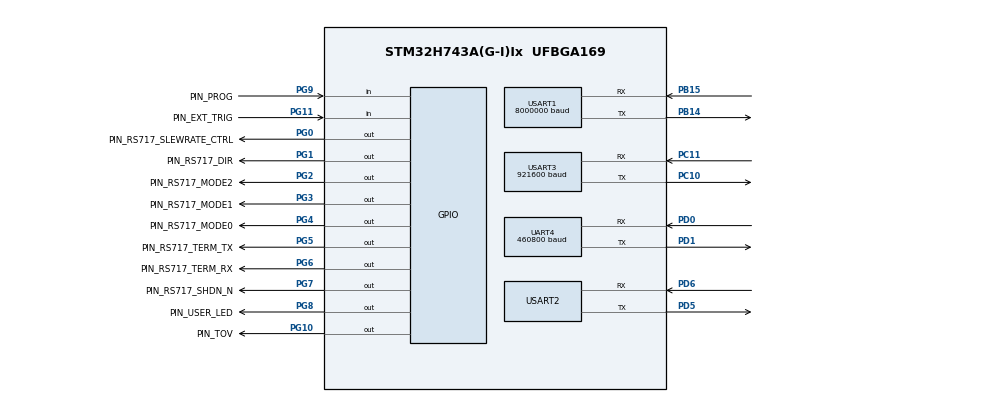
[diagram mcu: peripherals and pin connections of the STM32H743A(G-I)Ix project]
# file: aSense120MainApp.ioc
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CORTEX_M7.AccessPermission-Cortex_Memory_Protection_Unit_Region0_Settings=MPU_REGION_FULL_ACCESS
CORTEX_M7.AccessPermission_Spec=MPU_REGION_FULL_ACCESS
CORTEX_M7.BaseAddress-Cortex_Memory_Protection_Unit_Region0_Settings=0x2407F000
CORTEX_M7.BaseAddress_Spec=0x2407C000
CORTEX_M7.CPU_DCache=Enabled
CORTEX_M7.CPU_ICache=Enabled
CORTEX_M7.DisableExec_Spec=MPU_INSTRUCTION_ACCESS_ENABLE
CORTEX_M7.Enable-Cortex_Memory_Protection_Unit_Region0_Settings=MPU_REGION_ENABLE
CORTEX_M7.IsBufferable-Cortex_Memory_Protection_Unit_Region0_Settings=MPU_ACCESS_BUFFERABLE
CORTEX_M7.IsBufferable_Spec=MPU_ACCESS_BUFFERABLE
CORTEX_M7.IsShareable-Cortex_Memory_Protection_Unit_Region0_Settings=MPU_ACCESS_SHAREABLE
CORTEX_M7.MPU_Control=MPU_PRIVILEGED_DEFAULT
CORTEX_M7.Size-Cortex_Memory_Protection_Unit_Region0_Settings=MPU_REGION_SIZE_4KB
CORTEX_M7.Size_Spec=MPU_REGION_SIZE_16KB
CORTEX_M7.SubRegionDisable_Spec=0x0
CORTEX_M7.TypeExtField_Spec=MPU_TEX_LEVEL0
CORTEX_M7.default_mode_Activation=1
Dma.Request0=USART1_RX
Dma.Request1=USART1_TX
Dma.Request2=UART4_RX
Dma.Request3=UART4_TX
Dma.Request4=USART3_RX
Dma.Request5=USART3_TX
Dma.Request6=USART2_RX
Dma.Request7=USART2_TX
Dma.UART4_RX.2.Direction=DMA_PERIPH_TO_MEMORY
Dma.UART4_RX.2.EventEnable=DISABLE
Dma.UART4_RX.2.FIFOMode=DMA_FIFOMODE_DISABLE
Dma.UART4_RX.2.Instance=DMA1_Stream4
Dma.UART4_RX.2.MemDataAlignment=DMA_MDATAALIGN_BYTE
Dma.UART4_RX.2.MemInc=DMA_MINC_ENABLE
Dma.UART4_RX.2.Mode=DMA_NORMAL
Dma.UART4_RX.2.PeriphDataAlignment=DMA_PDATAALIGN_BYTE
Dma.UART4_RX.2.PeriphInc=DMA_PINC_DISABLE
Dma.UART4_RX.2.Polarity=HAL_DMAMUX_REQ_GEN_RISING
Dma.UART4_RX.2.Priority=DMA_PRIORITY_LOW
Dma.UART4_RX.2.RequestNumber=1
Dma.UART4_RX.2.SignalID=NONE
Dma.UART4_RX.2.SyncEnable=DISABLE
Dma.UART4_RX.2.SyncPolarity=HAL_DMAMUX_SYNC_NO_EVENT
Dma.UART4_RX.2.SyncRequestNumber=1
Dma.UART4_RX.2.SyncSignalID=NONE
Dma.UART4_TX.3.Direction=DMA_MEMORY_TO_PERIPH
Dma.UART4_TX.3.EventEnable=DISABLE
Dma.UART4_TX.3.FIFOMode=DMA_FIFOMODE_DISABLE
Dma.UART4_TX.3.Instance=DMA1_Stream5
Dma.UART4_TX.3.MemDataAlignment=DMA_MDATAALIGN_BYTE
Dma.UART4_TX.3.MemInc=DMA_MINC_ENABLE
Dma.UART4_TX.3.Mode=DMA_NORMAL
Dma.UART4_TX.3.PeriphDataAlignment=DMA_PDATAALIGN_BYTE
Dma.UART4_TX.3.PeriphInc=DMA_PINC_DISABLE
Dma.UART4_TX.3.Polarity=HAL_DMAMUX_REQ_GEN_RISING
Dma.UART4_TX.3.Priority=DMA_PRIORITY_LOW
Dma.UART4_TX.3.RequestNumber=1
Dma.UART4_TX.3.SignalID=NONE
Dma.UART4_TX.3.SyncEnable=DISABLE
Dma.UART4_TX.3.SyncPolarity=HAL_DMAMUX_SYNC_NO_EVENT
Dma.UART4_TX.3.SyncRequestNumber=1
Dma.UART4_TX.3.SyncSignalID=NONE
Dma.USART1_RX.0.Direction=DMA_PERIPH_TO_MEMORY
Dma.USART1_RX.0.EventEnable=DISABLE
Dma.USART1_RX.0.FIFOMode=DMA_FIFOMODE_DISABLE
Dma.USART1_RX.0.Instance=DMA1_Stream0
Dma.USART1_RX.0.MemDataAlignment=DMA_MDATAALIGN_BYTE
Dma.USART1_RX.0.MemInc=DMA_MINC_ENABLE
Dma.USART1_RX.0.Mode=DMA_NORMAL
Dma.USART1_RX.0.PeriphDataAlignment=DMA_PDATAALIGN_BYTE
Dma.USART1_RX.0.PeriphInc=DMA_PINC_DISABLE
Dma.USART1_RX.0.Polarity=HAL_DMAMUX_REQ_GEN_RISING
Dma.USART1_RX.0.Priority=DMA_PRIORITY_LOW
Dma.USART1_RX.0.RequestNumber=1
Dma.USART1_RX.0.SignalID=NONE
Dma.USART1_RX.0.SyncEnable=DISABLE
Dma.USART1_RX.0.SyncPolarity=HAL_DMAMUX_SYNC_NO_EVENT
Dma.USART1_RX.0.SyncRequestNumber=1
Dma.USART1_RX.0.SyncSignalID=NONE
Dma.USART1_TX.1.Direction=DMA_MEMORY_TO_PERIPH
Dma.USART1_TX.1.EventEnable=DISABLE
Dma.USART1_TX.1.FIFOMode=DMA_FIFOMODE_DISABLE
Dma.USART1_TX.1.Instance=DMA1_Stream1
Dma.USART1_TX.1.MemDataAlignment=DMA_MDATAALIGN_BYTE
Dma.USART1_TX.1.MemInc=DMA_MINC_ENABLE
Dma.USART1_TX.1.Mode=DMA_NORMAL
Dma.USART1_TX.1.PeriphDataAlignment=DMA_PDATAALIGN_BYTE
Dma.USART1_TX.1.PeriphInc=DMA_PINC_DISABLE
Dma.USART1_TX.1.Polarity=HAL_DMAMUX_REQ_GEN_RISING
Dma.USART1_TX.1.Priority=DMA_PRIORITY_LOW
Dma.USART1_TX.1.RequestNumber=1
Dma.USART1_TX.1.SignalID=NONE
Dma.USART1_TX.1.SyncEnable=DISABLE
Dma.USART1_TX.1.SyncPolarity=HAL_DMAMUX_SYNC_NO_EVENT
Dma.USART1_TX.1.SyncRequestNumber=1
Dma.USART1_TX.1.SyncSignalID=NONE
Dma.USART2_RX.6.Direction=DMA_PERIPH_TO_MEMORY
Dma.USART2_RX.6.EventEnable=DISABLE
Dma.USART2_RX.6.FIFOMode=DMA_FIFOMODE_DISABLE
Dma.USART2_RX.6.Instance=DMA1_Stream2
Dma.USART2_RX.6.MemDataAlignment=DMA_MDATAALIGN_BYTE
Dma.USART2_RX.6.MemInc=DMA_MINC_ENABLE
Dma.USART2_RX.6.Mode=DMA_NORMAL
Dma.USART2_RX.6.PeriphDataAlignment=DMA_PDATAALIGN_BYTE
Dma.USART2_RX.6.PeriphInc=DMA_PINC_DISABLE
Dma.USART2_RX.6.Polarity=HAL_DMAMUX_REQ_GEN_RISING
Dma.USART2_RX.6.Priority=DMA_PRIORITY_LOW
Dma.USART2_RX.6.RequestNumber=1
Dma.USART2_RX.6.SignalID=NONE
Dma.USART2_RX.6.SyncEnable=DISABLE
Dma.USART2_RX.6.SyncPolarity=HAL_DMAMUX_SYNC_NO_EVENT
Dma.USART2_RX.6.SyncRequestNumber=1
Dma.USART2_RX.6.SyncSignalID=NONE
Dma.USART2_TX.7.Direction=DMA_MEMORY_TO_PERIPH
Dma.USART2_TX.7.EventEnable=DISABLE
Dma.USART2_TX.7.FIFOMode=DMA_FIFOMODE_DISABLE
Dma.USART2_TX.7.Instance=DMA1_Stream3
Dma.USART2_TX.7.MemDataAlignment=DMA_MDATAALIGN_BYTE
Dma.USART2_TX.7.MemInc=DMA_MINC_ENABLE
Dma.USART2_TX.7.Mode=DMA_NORMAL
Dma.USART2_TX.7.PeriphDataAlignment=DMA_PDATAALIGN_BYTE
Dma.USART2_TX.7.PeriphInc=DMA_PINC_DISABLE
Dma.USART2_TX.7.Polarity=HAL_DMAMUX_REQ_GEN_RISING
Dma.USART2_TX.7.Priority=DMA_PRIORITY_LOW
Dma.USART2_TX.7.RequestNumber=1
Dma.USART2_TX.7.SignalID=NONE
Dma.USART2_TX.7.SyncEnable=DISABLE
Dma.USART2_TX.7.SyncPolarity=HAL_DMAMUX_SYNC_NO_EVENT
Dma.USART2_TX.7.SyncRequestNumber=1
Dma.USART2_TX.7.SyncSignalID=NONE
Dma.USART3_RX.4.Direction=DMA_PERIPH_TO_MEMORY
Dma.USART3_RX.4.EventEnable=DISABLE
Dma.USART3_RX.4.FIFOMode=DMA_FIFOMODE_DISABLE
Dma.USART3_RX.4.Instance=DMA2_Stream3
Dma.USART3_RX.4.MemDataAlignment=DMA_MDATAALIGN_BYTE
Dma.USART3_RX.4.MemInc=DMA_MINC_ENABLE
Dma.USART3_RX.4.Mode=DMA_NORMAL
Dma.USART3_RX.4.PeriphDataAlignment=DMA_PDATAALIGN_BYTE
Dma.USART3_RX.4.PeriphInc=DMA_PINC_DISABLE
Dma.USART3_RX.4.Polarity=HAL_DMAMUX_REQ_GEN_RISING
Dma.USART3_RX.4.Priority=DMA_PRIORITY_LOW
Dma.USART3_RX.4.RequestNumber=1
Dma.USART3_RX.4.SignalID=NONE
Dma.USART3_RX.4.SyncEnable=DISABLE
Dma.USART3_RX.4.SyncPolarity=HAL_DMAMUX_SYNC_NO_EVENT
Dma.USART3_RX.4.SyncRequestNumber=1
Dma.USART3_RX.4.SyncSignalID=NONE
Dma.USART3_TX.5.Direction=DMA_MEMORY_TO_PERIPH
Dma.USART3_TX.5.EventEnable=DISABLE
Dma.USART3_TX.5.FIFOMode=DMA_FIFOMODE_DISABLE
Dma.USART3_TX.5.Instance=DMA2_Stream2
Dma.USART3_TX.5.MemDataAlignment=DMA_MDATAALIGN_BYTE
Dma.USART3_TX.5.MemInc=DMA_MINC_ENABLE
Dma.USART3_TX.5.Mode=DMA_NORMAL
Dma.USART3_TX.5.PeriphDataAlignment=DMA_PDATAALIGN_BYTE
Dma.USART3_TX.5.PeriphInc=DMA_PINC_DISABLE
Dma.USART3_TX.5.Polarity=HAL_DMAMUX_REQ_GEN_RISING
Dma.USART3_TX.5.Priority=DMA_PRIORITY_LOW
Dma.USART3_TX.5.RequestNumber=1
Dma.USART3_TX.5.SignalID=NONE
Dma.USART3_TX.5.SyncEnable=DISABLE
Dma.USART3_TX.5.SyncPolarity=HAL_DMAMUX_SYNC_NO_EVENT
Dma.USART3_TX.5.SyncRequestNumber=1
Dma.USART3_TX.5.SyncSignalID=NONE
Mcu.Family=STM32H7
Mcu.Name=STM32H743A(G-I)Ix
Mcu.Package=UFBGA169
Mcu.UserConstants=UART_RS717,$$_USART3_IP_HANDLE_$$;UART_EXT_IF,$$_USART1_IP_HANDLE_$$;UART_DELTAIMU,$$_UART4_IP_HANDLE_$$
NVIC.DMA1_Stream0_IRQn=true\:0\:0\:true\:false\:true\:true\:false\:true\:true
NVIC.DMA1_Stream1_IRQn=true\:0\:0\:true\:false\:true\:true\:false\:true\:true
NVIC.DMA1_Stream2_IRQn=true\:0\:0\:false\:false\:true\:true\:false\:true\:true
NVIC.DMA1_Stream3_IRQn=true\:0\:0\:false\:false\:true\:true\:false\:true\:true
NVIC.DMA1_Stream4_IRQn=true\:0\:0\:true\:false\:true\:true\:false\:true\:true
NVIC.DMA1_Stream5_IRQn=true\:0\:0\:true\:false\:true\:true\:false\:true\:true
NVIC.DMA2_Stream2_IRQn=true\:0\:0\:false\:false\:true\:false\:false\:true\:true
NVIC.DMA2_Stream3_IRQn=true\:0\:0\:false\:false\:true\:false\:false\:true\:true
NVIC.PriorityGroup=NVIC_PRIORITYGROUP_4
NVIC.TIM3_IRQn=true\:0\:0\:false\:false\:true\:false\:true\:true\:true
NVIC.TIM6_DAC_IRQn=true\:15\:0\:true\:false\:true\:false\:false\:true\:true
NVIC.TimeBase=TIM6_DAC_IRQn
NVIC.TimeBaseIP=TIM6
NVIC.UART4_IRQn=true\:0\:0\:true\:false\:true\:false\:true\:true\:true
NVIC.USART1_IRQn=true\:0\:0\:true\:false\:true\:false\:true\:true\:true
NVIC.USART2_IRQn=true\:0\:0\:false\:false\:true\:false\:true\:true\:true
NVIC.USART3_IRQn=true\:0\:0\:true\:false\:true\:false\:true\:true\:true
PA13\ (JTMS/SWDIO).Mode=Serial_Wire
PA13\ (JTMS/SWDIO).Signal=DEBUG_JTMS-SWDIO
PA14\ (JTCK/SWCLK).Mode=Serial_Wire
PA14\ (JTCK/SWCLK).Signal=DEBUG_JTCK-SWCLK
PB14.GPIO_PuPd=GPIO_PULLUP
PB14.GPIO_Speed=GPIO_SPEED_FREQ_VERY_HIGH
PB14.Mode=Asynchronous
PB14.Signal=USART1_TX
PB15.GPIO_PuPd=GPIO_PULLUP
PB15.GPIO_Speed=GPIO_SPEED_FREQ_VERY_HIGH
PB15.Mode=Asynchronous
PB15.Signal=USART1_RX
PC10.GPIO_PuPd=GPIO_PULLUP
PC10.GPIO_Speed=GPIO_SPEED_FREQ_VERY_HIGH
PC10.Mode=Asynchronous
PC10.Signal=USART3_TX
PC11.GPIO_PuPd=GPIO_PULLUP
PC11.GPIO_Speed=GPIO_SPEED_FREQ_VERY_HIGH
PC11.Mode=Asynchronous
PC11.Signal=USART3_RX
PC14-OSC32_IN\ (OSC32_IN).Mode=LSE-External-Oscillator
PC14-OSC32_IN\ (OSC32_IN).Signal=RCC_OSC32_IN
PC15-OSC32_OUT\ (OSC32_OUT).Mode=LSE-External-Oscillator
PC15-OSC32_OUT\ (OSC32_OUT).Signal=RCC_OSC32_OUT
PD0.GPIO_PuPd=GPIO_PULLUP
PD0.Mode=Asynchronous
PD0.Signal=UART4_RX
PD1.GPIO_PuPd=GPIO_PULLUP
PD1.Mode=Asynchronous
PD1.Signal=UART4_TX
PD5.GPIO_PuPd=GPIO_PULLUP
PD5.Mode=Asynchronous
PD5.Signal=USART2_TX
PD6.GPIO_PuPd=GPIO_PULLUP
PD6.Mode=Asynchronous
PD6.Signal=USART2_RX
PG0.GPIO_Label=PIN_RS717_SLEWRATE_CTRL
PG0.Signal=GPIO_Output
PG1.GPIO_Label=PIN_RS717_DIR
PG1.Signal=GPIO_Output
PG10.GPIO_Label=PIN_TOV
PG10.Signal=GPIO_Output
PG11.GPIO_Label=PIN_EXT_TRIG
PG11.GPIO_PuPd=GPIO_PULLDOWN
PG11.Signal=GPIO_Input
PG2.GPIO_Label=PIN_RS717_MODE2
PG2.GPIO_ModeDefaultOutputPP=GPIO_MODE_OUTPUT_PP
PG2.GPIO_PuPd=GPIO_NOPULL
PG2.PinState=GPIO_PIN_SET
PG2.Signal=GPIO_Output
PG3.GPIO_Label=PIN_RS717_MODE1
PG3.Signal=GPIO_Output
PG4.GPIO_Label=PIN_RS717_MODE0
PG4.Signal=GPIO_Output
PG5.GPIO_Label=PIN_RS717_TERM_TX
PG5.Signal=GPIO_Output
PG6.GPIO_Label=PIN_RS717_TERM_RX
PG6.Signal=GPIO_Output
PG7.GPIO_Label=PIN_RS717_SHDN_N
PG7.Signal=GPIO_Output
PG8.GPIO_Label=PIN_USER_LED
PG8.Signal=GPIO_Output
PG9.GPIO_Label=PIN_PROG
PG9.GPIO_PuPd=GPIO_PULLDOWN
PG9.Signal=GPIO_Input
PH0-OSC_IN\ (PH0).Mode=HSE-External-Oscillator
PH0-OSC_IN\ (PH0).Signal=RCC_OSC_IN
PH1-OSC_OUT\ (PH1).Mode=HSE-External-Oscillator
PH1-OSC_OUT\ (PH1).Signal=RCC_OSC_OUT
ProjectManager.HeapSize=0x30000
ProjectManager.StackSize=0x1000
ProjectManager.TargetToolchain=STM32CubeIDE
RCC.ADCFreq_Value=75000000
RCC.APB1Freq_Value=100000000
RCC.APB2Freq_Value=100000000
RCC.APB3Freq_Value=100000000
RCC.APB4Freq_Value=100000000
RCC.CortexFreq_Value=400000000
RCC.D1PPRE=RCC_APB3_DIV2
RCC.D2PPRE1=RCC_APB1_DIV2
RCC.D2PPRE2=RCC_APB2_DIV2
RCC.D3PPRE=RCC_APB4_DIV2
RCC.DIVM1=2
RCC.DIVM2=2
RCC.DIVM3=2
RCC.DIVN1=64
RCC.DIVN2=12
RCC.DIVN3=12
RCC.HCLKFreq_Value=200000000
RCC.HPRE=RCC_HCLK_DIV2
RCC.PLL2FRACN=0
RCC.PLL3FRACN=0
RCC.PLLFRACN=0
RCC.PLLSourceVirtual=RCC_PLLSOURCE_HSE
RCC.SYSCLKFreq_VALUE=400000000
RCC.SYSCLKSource=RCC_SYSCLKSOURCE_PLLCLK
RCC.Spi45ClockSelection=RCC_SPI45CLKSOURCE_HSI
RCC.USART16CLockSelection=RCC_USART16CLKSOURCE_HSI
RCC.USART234578CLockSelection=RCC_USART234578CLKSOURCE_HSI
RCC.USBFreq_Value=400000000
STMicroelectronics.X-CUBE-AZRTOS-H7.3.3.0.TX_APP_GENERATE_INIT_CODE=true
STMicroelectronics.X-CUBE-AZRTOS-H7.3.3.0.TX_APP_MEM_POOL_SIZE=180*1024
STMicroelectronics.X-CUBE-AZRTOS-H7.3.3.0.TX_BASEPRI_SUPPORT=0
STMicroelectronics.X-CUBE-AZRTOS-H7.3.3.0.TX_BASEPRI_VALUE=8
STMicroelectronics.X-CUBE-AZRTOS-H7.3.3.0.TX_BLOCK_POOL_ENABLE_PERFORMANCE_INFO=1
STMicroelectronics.X-CUBE-AZRTOS-H7.3.3.0.TX_BYTE_POOL_ENABLE_PERFORMANCE_INFO=1
STMicroelectronics.X-CUBE-AZRTOS-H7.3.3.0.TX_ENABLE_STACK_CHECKING=1
STMicroelectronics.X-CUBE-AZRTOS-H7.3.3.0.TX_EVENT_FLAGS_ENABLE_PERFORMANCE_INFO=1
STMicroelectronics.X-CUBE-AZRTOS-H7.3.3.0.TX_INLINE_THREAD_RESUME_SUSPEND=1
STMicroelectronics.X-CUBE-AZRTOS-H7.3.3.0.TX_MAX_PRIORITIES=64
STMicroelectronics.X-CUBE-AZRTOS-H7.3.3.0.TX_MUTEX_ENABLE_PERFORMANCE_INFO=1
STMicroelectronics.X-CUBE-AZRTOS-H7.3.3.0.TX_QUEUE_ENABLE_PERFORMANCE_INFO=1
STMicroelectronics.X-CUBE-AZRTOS-H7.3.3.0.TX_SEMAPHORE_ENABLE_PERFORMANCE_INFO=1
STMicroelectronics.X-CUBE-AZRTOS-H7.3.3.0.TX_THREAD_ENABLE_PERFORMANCE_INFO=1
STMicroelectronics.X-CUBE-AZRTOS-H7.3.3.0.TX_TIMER_ENABLE_PERFORMANCE_INFO=1
STMicroelectronics.X-CUBE-AZRTOS-H7.3.3.0.TX_TIMER_THREAD_STACK_SIZE=2048
STMicroelectronics.X-CUBE-AZRTOS-H7.3.3.0.TX_TIMER_TICKS_PER_SECOND=1000
STMicroelectronics.X-CUBE-AZRTOS-H7.3.3.0.ThreadXCcRTOSJjThreadXJjCore=true
STMicroelectronics.X-CUBE-AZRTOS-H7.3.3.0.ThreadXCcRTOSJjThreadXJjPerformanceInfo=true
STMicroelectronics.X-CUBE-AZRTOS-H7.3.3.0.ThreadX_Version=6.2.1
STMicroelectronics.X-CUBE-AZRTOS-H7.3.3.0_IsAnAzureRtosMw=true
TIM3.ClockDivision=TIM_CLOCKDIVISION_DIV4
TIM3.Period=400-1
TIM3.Prescaler=500-1
UART4.BaudRate=460800
UART4.OverSampling=UART_OVERSAMPLING_16
UART4.OverrunDisableParam=UART_ADVFEATURE_OVERRUN_DISABLE
USART1.BaudRate=8000000
USART1.OneBitSampling=UART_ONE_BIT_SAMPLE_DISABLE
USART1.OverSampling=UART_OVERSAMPLING_8
USART1.VirtualMode-Asynchronous=VM_ASYNC
USART2.OverrunDisableParam=ADVFEATURE_OVERRUN_DISABLE
USART2.VirtualMode-Asynchronous=VM_ASYNC
USART3.BaudRate=921600
USART3.FIFOMode=FIFOMODE_DISABLE
USART3.Mode=MODE_TX_RX
USART3.OverSampling=UART_OVERSAMPLING_16
USART3.OverrunDisableParam=ADVFEATURE_OVERRUN_ENABLE
USART3.VirtualMode-Asynchronous=VM_ASYNC
VP_MEMORYMAP_VS_MEMORYMAP.Mode=CurAppReg
VP_STMicroelectronics.X-CUBE-AZRTOS-H7_VS_RTOSJjThreadX_6.4.0_3.3.0.Mode=RTOSJjThreadX
VP_SYS_VS_tim6.Mode=TIM6
VP_TIM3_VS_ClockSourceINT.Mode=Internal
board=custom

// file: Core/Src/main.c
/* USER CODE BEGIN Header */
/**
  ******************************************************************************
  * @file           : main.c
  * @brief          : Main program body
  ******************************************************************************
  * @attention
  *
  * Copyright (c) 2025 STMicroelectronics.
  * All rights reserved.
  *
  * This software is licensed under terms that can be found in the LICENSE file
  * in the root directory of this software component.
  * If no LICENSE file comes with this software, it is provided AS-IS.
  *
  ******************************************************************************
  */
/* USER CODE END Header */
#include "app_threadx.h"
#include "main.h"

TIM_HandleTypeDef htim3;

UART_HandleTypeDef huart4;
UART_HandleTypeDef huart1;
UART_HandleTypeDef huart2;
UART_HandleTypeDef huart3;
DMA_HandleTypeDef hdma_uart4_rx;
DMA_HandleTypeDef hdma_uart4_tx;
DMA_HandleTypeDef hdma_usart1_rx;
DMA_HandleTypeDef hdma_usart1_tx;
DMA_HandleTypeDef hdma_usart2_rx;
DMA_HandleTypeDef hdma_usart2_tx;
DMA_HandleTypeDef hdma_usart3_rx;
DMA_HandleTypeDef hdma_usart3_tx;

/* USER CODE BEGIN PV */
#if !defined(MAX_UART_DEVICE_CNT)
#define MAX_UART_DEVICE_CNT 7
#endif
UART_HandleTypeDef *uart_created_list[MAX_UART_DEVICE_CNT] = {NULL};
/* USER CODE END PV */

void SystemClock_Config(void);
static void MPU_Config(void);
static void MX_GPIO_Init(void);
static void MX_DMA_Init(void);
static void MX_USART3_UART_Init(void);
static void MX_USART1_UART_Init(void);
static void MX_UART4_Init(void);
static void MX_TIM3_Init(void);
static void MX_USART2_UART_Init(void);

int main(void)
{

  /* MPU Configuration--------------------------------------------------------*/
  MPU_Config();

  /* Enable the CPU Cache */

  /* Enable I-Cache---------------------------------------------------------*/
  SCB_EnableICache();

  /* Enable D-Cache---------------------------------------------------------*/
  SCB_EnableDCache();

  /* MCU Configuration--------------------------------------------------------*/

  /* Reset of all peripherals, Initializes the Flash interface and the Systick. */
  HAL_Init();

  /* Configure the system clock */
  SystemClock_Config();

  /* Initialize all configured peripherals */
  MX_GPIO_Init();
  MX_DMA_Init();
  MX_USART3_UART_Init();
  MX_USART1_UART_Init();
  MX_UART4_Init();
  MX_TIM3_Init();
  MX_USART2_UART_Init();

  MX_ThreadX_Init();

  /* We should never get here as control is now taken by the scheduler */

  /* Infinite loop */
  while (1)
  {

  }
}

void SystemClock_Config(void)
{
  RCC_OscInitTypeDef RCC_OscInitStruct = {0};
  RCC_ClkInitTypeDef RCC_ClkInitStruct = {0};

  /** Supply configuration update enable
  */
  HAL_PWREx_ConfigSupply(PWR_LDO_SUPPLY);

  /** Configure the main internal regulator output voltage
  */
  __HAL_PWR_VOLTAGESCALING_CONFIG(PWR_REGULATOR_VOLTAGE_SCALE1);

  while(!__HAL_PWR_GET_FLAG(PWR_FLAG_VOSRDY)) {}

  /** Initializes the RCC Oscillators according to the specified parameters
  * in the RCC_OscInitTypeDef structure.
  */
  RCC_OscInitStruct.OscillatorType = RCC_OSCILLATORTYPE_HSI|RCC_OSCILLATORTYPE_HSE;
  RCC_OscInitStruct.HSEState = RCC_HSE_ON;
  RCC_OscInitStruct.HSIState = RCC_HSI_DIV1;
  RCC_OscInitStruct.HSICalibrationValue = RCC_HSICALIBRATION_DEFAULT;
  RCC_OscInitStruct.PLL.PLLState = RCC_PLL_ON;
  RCC_OscInitStruct.PLL.PLLSource = RCC_PLLSOURCE_HSE;
  RCC_OscInitStruct.PLL.PLLM = 2;
  RCC_OscInitStruct.PLL.PLLN = 64;
  RCC_OscInitStruct.PLL.PLLP = 2;
  RCC_OscInitStruct.PLL.PLLQ = 2;
  RCC_OscInitStruct.PLL.PLLR = 2;
  RCC_OscInitStruct.PLL.PLLRGE = RCC_PLL1VCIRANGE_3;
  RCC_OscInitStruct.PLL.PLLVCOSEL = RCC_PLL1VCOWIDE;
  RCC_OscInitStruct.PLL.PLLFRACN = 0;
  if (HAL_RCC_OscConfig(&RCC_OscInitStruct) != HAL_OK)
  {
    Error_Handler();
  }

  /** Initializes the CPU, AHB and APB buses clocks
  */
  RCC_ClkInitStruct.ClockType = RCC_CLOCKTYPE_HCLK|RCC_CLOCKTYPE_SYSCLK
                              |RCC_CLOCKTYPE_PCLK1|RCC_CLOCKTYPE_PCLK2
                              |RCC_CLOCKTYPE_D3PCLK1|RCC_CLOCKTYPE_D1PCLK1;
  RCC_ClkInitStruct.SYSCLKSource = RCC_SYSCLKSOURCE_PLLCLK;
  RCC_ClkInitStruct.SYSCLKDivider = RCC_SYSCLK_DIV1;
  RCC_ClkInitStruct.AHBCLKDivider = RCC_HCLK_DIV2;
  RCC_ClkInitStruct.APB3CLKDivider = RCC_APB3_DIV2;
  RCC_ClkInitStruct.APB1CLKDivider = RCC_APB1_DIV2;
  RCC_ClkInitStruct.APB2CLKDivider = RCC_APB2_DIV2;
  RCC_ClkInitStruct.APB4CLKDivider = RCC_APB4_DIV2;

  if (HAL_RCC_ClockConfig(&RCC_ClkInitStruct, FLASH_LATENCY_2) != HAL_OK)
  {
    Error_Handler();
  }
}

static void MX_TIM3_Init(void)
{

  TIM_ClockConfigTypeDef sClockSourceConfig = {0};
  TIM_MasterConfigTypeDef sMasterConfig = {0};

  htim3.Instance = TIM3;
  htim3.Init.Prescaler = 500-1;
  htim3.Init.CounterMode = TIM_COUNTERMODE_UP;
  htim3.Init.Period = 400-1;
  htim3.Init.ClockDivision = TIM_CLOCKDIVISION_DIV4;
  htim3.Init.AutoReloadPreload = TIM_AUTORELOAD_PRELOAD_DISABLE;
  if (HAL_TIM_Base_Init(&htim3) != HAL_OK)
  {
    Error_Handler();
  }
  sClockSourceConfig.ClockSource = TIM_CLOCKSOURCE_INTERNAL;
  if (HAL_TIM_ConfigClockSource(&htim3, &sClockSourceConfig) != HAL_OK)
  {
    Error_Handler();
  }
  sMasterConfig.MasterOutputTrigger = TIM_TRGO_RESET;
  sMasterConfig.MasterSlaveMode = TIM_MASTERSLAVEMODE_DISABLE;
  if (HAL_TIMEx_MasterConfigSynchronization(&htim3, &sMasterConfig) != HAL_OK)
  {
    Error_Handler();
  }

}

static void MX_UART4_Init(void)
{

  huart4.Instance = UART4;
  huart4.Init.BaudRate = 460800;
  huart4.Init.WordLength = UART_WORDLENGTH_8B;
  huart4.Init.StopBits = UART_STOPBITS_1;
  huart4.Init.Parity = UART_PARITY_NONE;
  huart4.Init.Mode = UART_MODE_TX_RX;
  huart4.Init.HwFlowCtl = UART_HWCONTROL_NONE;
  huart4.Init.OverSampling = UART_OVERSAMPLING_16;
  huart4.Init.OneBitSampling = UART_ONE_BIT_SAMPLE_DISABLE;
  huart4.Init.ClockPrescaler = UART_PRESCALER_DIV1;
  huart4.AdvancedInit.AdvFeatureInit = UART_ADVFEATURE_RXOVERRUNDISABLE_INIT;
  huart4.AdvancedInit.OverrunDisable = UART_ADVFEATURE_OVERRUN_DISABLE;
  if (HAL_UART_Init(&huart4) != HAL_OK)
  {
    Error_Handler();
  }
  if (HAL_UARTEx_SetTxFifoThreshold(&huart4, UART_TXFIFO_THRESHOLD_1_8) != HAL_OK)
  {
    Error_Handler();
  }
  if (HAL_UARTEx_SetRxFifoThreshold(&huart4, UART_RXFIFO_THRESHOLD_1_8) != HAL_OK)
  {
    Error_Handler();
  }
  if (HAL_UARTEx_DisableFifoMode(&huart4) != HAL_OK)
  {
    Error_Handler();
  }
  /* USER CODE BEGIN UART4_Init 2 */
  uart_created_list[3] = &huart4;
  /* USER CODE END UART4_Init 2 */

}

static void MX_USART1_UART_Init(void)
{

  huart1.Instance = USART1;
  huart1.Init.BaudRate = 8000000;
  huart1.Init.WordLength = UART_WORDLENGTH_8B;
  huart1.Init.StopBits = UART_STOPBITS_1;
  huart1.Init.Parity = UART_PARITY_NONE;
  huart1.Init.Mode = UART_MODE_TX_RX;
  huart1.Init.HwFlowCtl = UART_HWCONTROL_NONE;
  huart1.Init.OverSampling = UART_OVERSAMPLING_8;
  huart1.Init.OneBitSampling = UART_ONE_BIT_SAMPLE_DISABLE;
  huart1.Init.ClockPrescaler = UART_PRESCALER_DIV1;
  huart1.AdvancedInit.AdvFeatureInit = UART_ADVFEATURE_NO_INIT;
  if (HAL_UART_Init(&huart1) != HAL_OK)
  {
    Error_Handler();
  }
  if (HAL_UARTEx_SetTxFifoThreshold(&huart1, UART_TXFIFO_THRESHOLD_1_8) != HAL_OK)
  {
    Error_Handler();
  }
  if (HAL_UARTEx_SetRxFifoThreshold(&huart1, UART_RXFIFO_THRESHOLD_1_8) != HAL_OK)
  {
    Error_Handler();
  }
  if (HAL_UARTEx_DisableFifoMode(&huart1) != HAL_OK)
  {
    Error_Handler();
  }
  /* USER CODE BEGIN USART1_Init 2 */
  uart_created_list[0] = &huart1;
  /* USER CODE END USART1_Init 2 */

}

static void MX_USART2_UART_Init(void)
{

  huart2.Instance = USART2;
  huart2.Init.BaudRate = 115200;
  huart2.Init.WordLength = UART_WORDLENGTH_8B;
  huart2.Init.StopBits = UART_STOPBITS_1;
  huart2.Init.Parity = UART_PARITY_NONE;
  huart2.Init.Mode = UART_MODE_TX_RX;
  huart2.Init.HwFlowCtl = UART_HWCONTROL_NONE;
  huart2.Init.OverSampling = UART_OVERSAMPLING_16;
  huart2.Init.OneBitSampling = UART_ONE_BIT_SAMPLE_DISABLE;
  huart2.Init.ClockPrescaler = UART_PRESCALER_DIV1;
  huart2.AdvancedInit.AdvFeatureInit = UART_ADVFEATURE_RXOVERRUNDISABLE_INIT;
  huart2.AdvancedInit.OverrunDisable = UART_ADVFEATURE_OVERRUN_DISABLE;
  if (HAL_UART_Init(&huart2) != HAL_OK)
  {
    Error_Handler();
  }
  if (HAL_UARTEx_SetTxFifoThreshold(&huart2, UART_TXFIFO_THRESHOLD_1_8) != HAL_OK)
  {
    Error_Handler();
  }
  if (HAL_UARTEx_SetRxFifoThreshold(&huart2, UART_RXFIFO_THRESHOLD_1_8) != HAL_OK)
  {
    Error_Handler();
  }
  if (HAL_UARTEx_DisableFifoMode(&huart2) != HAL_OK)
  {
    Error_Handler();
  }
  /* USER CODE BEGIN USART2_Init 2 */
  uart_created_list[1] = &huart2;
  /* USER CODE END USART2_Init 2 */

}

static void MX_USART3_UART_Init(void)
{

  huart3.Instance = USART3;
  huart3.Init.BaudRate = 921600;
  huart3.Init.WordLength = UART_WORDLENGTH_8B;
  huart3.Init.StopBits = UART_STOPBITS_1;
  huart3.Init.Parity = UART_PARITY_NONE;
  huart3.Init.Mode = UART_MODE_TX_RX;
  huart3.Init.HwFlowCtl = UART_HWCONTROL_NONE;
  huart3.Init.OverSampling = UART_OVERSAMPLING_16;
  huart3.Init.OneBitSampling = UART_ONE_BIT_SAMPLE_DISABLE;
  huart3.Init.ClockPrescaler = UART_PRESCALER_DIV1;
  huart3.AdvancedInit.AdvFeatureInit = UART_ADVFEATURE_NO_INIT;
  if (HAL_UART_Init(&huart3) != HAL_OK)
  {
    Error_Handler();
  }
  if (HAL_UARTEx_SetTxFifoThreshold(&huart3, UART_TXFIFO_THRESHOLD_1_8) != HAL_OK)
  {
    Error_Handler();
  }
  if (HAL_UARTEx_SetRxFifoThreshold(&huart3, UART_RXFIFO_THRESHOLD_1_8) != HAL_OK)
  {
    Error_Handler();
  }
  if (HAL_UARTEx_DisableFifoMode(&huart3) != HAL_OK)
  {
    Error_Handler();
  }
  /* USER CODE BEGIN USART3_Init 2 */
  uart_created_list[2] = &huart3;
  /* USER CODE END USART3_Init 2 */

}

static void MX_DMA_Init(void)
{

  /* DMA controller clock enable */
  __HAL_RCC_DMA1_CLK_ENABLE();
  __HAL_RCC_DMA2_CLK_ENABLE();

  /* DMA interrupt init */
  /* DMA1_Stream0_IRQn interrupt configuration */
  HAL_NVIC_SetPriority(DMA1_Stream0_IRQn, 0, 0);
  HAL_NVIC_EnableIRQ(DMA1_Stream0_IRQn);
  /* DMA1_Stream1_IRQn interrupt configuration */
  HAL_NVIC_SetPriority(DMA1_Stream1_IRQn, 0, 0);
  HAL_NVIC_EnableIRQ(DMA1_Stream1_IRQn);
  /* DMA1_Stream2_IRQn interrupt configuration */
  HAL_NVIC_SetPriority(DMA1_Stream2_IRQn, 0, 0);
  HAL_NVIC_EnableIRQ(DMA1_Stream2_IRQn);
  /* DMA1_Stream3_IRQn interrupt configuration */
  HAL_NVIC_SetPriority(DMA1_Stream3_IRQn, 0, 0);
  HAL_NVIC_EnableIRQ(DMA1_Stream3_IRQn);
  /* DMA1_Stream4_IRQn interrupt configuration */
  HAL_NVIC_SetPriority(DMA1_Stream4_IRQn, 0, 0);
  HAL_NVIC_EnableIRQ(DMA1_Stream4_IRQn);
  /* DMA1_Stream5_IRQn interrupt configuration */
  HAL_NVIC_SetPriority(DMA1_Stream5_IRQn, 0, 0);
  HAL_NVIC_EnableIRQ(DMA1_Stream5_IRQn);
  /* DMA2_Stream2_IRQn interrupt configuration */
  HAL_NVIC_SetPriority(DMA2_Stream2_IRQn, 0, 0);
  HAL_NVIC_EnableIRQ(DMA2_Stream2_IRQn);
  /* DMA2_Stream3_IRQn interrupt configuration */
  HAL_NVIC_SetPriority(DMA2_Stream3_IRQn, 0, 0);
  HAL_NVIC_EnableIRQ(DMA2_Stream3_IRQn);

}

static void MX_GPIO_Init(void)
{
  GPIO_InitTypeDef GPIO_InitStruct = {0};

  /* GPIO Ports Clock Enable */
  __HAL_RCC_GPIOG_CLK_ENABLE();
  __HAL_RCC_GPIOD_CLK_ENABLE();
  __HAL_RCC_GPIOC_CLK_ENABLE();
  __HAL_RCC_GPIOA_CLK_ENABLE();
  __HAL_RCC_GPIOH_CLK_ENABLE();
  __HAL_RCC_GPIOB_CLK_ENABLE();

  /*Configure GPIO pin Output Level */
  HAL_GPIO_WritePin(GPIOG, PIN_TOV_Pin|PIN_RS717_MODE0_Pin|PIN_RS717_TERM_RX_Pin|PIN_RS717_SHDN_N_Pin
                          |PIN_USER_LED_Pin|PIN_RS717_MODE1_Pin|PIN_RS717_TERM_TX_Pin|PIN_RS717_SLEWRATE_CTRL_Pin
                          |PIN_RS717_DIR_Pin, GPIO_PIN_RESET);

  /*Configure GPIO pin Output Level */
  HAL_GPIO_WritePin(PIN_RS717_MODE2_GPIO_Port, PIN_RS717_MODE2_Pin, GPIO_PIN_SET);

  /*Configure GPIO pins : PIN_TOV_Pin PIN_RS717_MODE0_Pin PIN_RS717_TERM_RX_Pin PIN_RS717_SHDN_N_Pin
                           PIN_USER_LED_Pin PIN_RS717_MODE2_Pin PIN_RS717_MODE1_Pin PIN_RS717_TERM_TX_Pin
                           PIN_RS717_SLEWRATE_CTRL_Pin PIN_RS717_DIR_Pin */
  GPIO_InitStruct.Pin = PIN_TOV_Pin|PIN_RS717_MODE0_Pin|PIN_RS717_TERM_RX_Pin|PIN_RS717_SHDN_N_Pin
                          |PIN_USER_LED_Pin|PIN_RS717_MODE2_Pin|PIN_RS717_MODE1_Pin|PIN_RS717_TERM_TX_Pin
                          |PIN_RS717_SLEWRATE_CTRL_Pin|PIN_RS717_DIR_Pin;
  GPIO_InitStruct.Mode = GPIO_MODE_OUTPUT_PP;
  GPIO_InitStruct.Pull = GPIO_NOPULL;
  GPIO_InitStruct.Speed = GPIO_SPEED_FREQ_LOW;
  HAL_GPIO_Init(GPIOG, &GPIO_InitStruct);

  /*Configure GPIO pins : PIN_EXT_TRIG_Pin PIN_PROG_Pin */
  GPIO_InitStruct.Pin = PIN_EXT_TRIG_Pin|PIN_PROG_Pin;
  GPIO_InitStruct.Mode = GPIO_MODE_INPUT;
  GPIO_InitStruct.Pull = GPIO_PULLDOWN;
  HAL_GPIO_Init(GPIOG, &GPIO_InitStruct);

}

 /* MPU Configuration */

void MPU_Config(void)
{
  MPU_Region_InitTypeDef MPU_InitStruct = {0};

  /* Disables the MPU */
  HAL_MPU_Disable();

  /** Initializes and configures the Region and the memory to be protected
  */
  MPU_InitStruct.Enable = MPU_REGION_ENABLE;
  MPU_InitStruct.Number = MPU_REGION_NUMBER0;
  MPU_InitStruct.BaseAddress = 0x24078000;
  MPU_InitStruct.Size = MPU_REGION_SIZE_32KB;
  MPU_InitStruct.SubRegionDisable = 0x0;
  MPU_InitStruct.TypeExtField = MPU_TEX_LEVEL0;
  MPU_InitStruct.AccessPermission = MPU_REGION_FULL_ACCESS;
  MPU_InitStruct.DisableExec = MPU_INSTRUCTION_ACCESS_ENABLE;
  MPU_InitStruct.IsShareable = MPU_ACCESS_SHAREABLE;
  MPU_InitStruct.IsCacheable = MPU_ACCESS_NOT_CACHEABLE;
  MPU_InitStruct.IsBufferable = MPU_ACCESS_BUFFERABLE;

  HAL_MPU_ConfigRegion(&MPU_InitStruct);
  /* Enables the MPU */
  HAL_MPU_Enable(MPU_PRIVILEGED_DEFAULT);

}

void HAL_TIM_PeriodElapsedCallback(TIM_HandleTypeDef *htim)
{
  if (htim->Instance == TIM6)
  {
    HAL_IncTick();
  }
}

void Error_Handler(void)
{
  __disable_irq();
  while (1)
  {
  }
}
